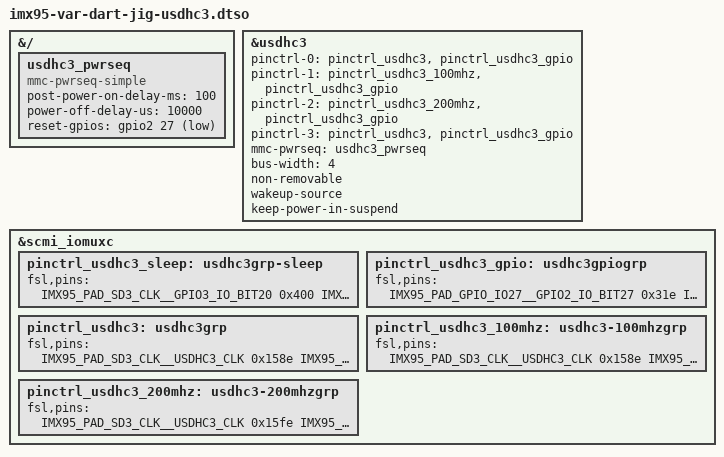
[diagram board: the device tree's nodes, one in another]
// SPDX-License-Identifier: (GPL-2.0+ OR MIT)
/*
 * Copyright 2023 NXP
 * Copyright 2024-2025 Variscite Ltd.
 */

#include "imx95-pinfunc.h"
#include <dt-bindings/gpio/gpio.h>

/dts-v1/;
/plugin/;
&{/} {
	usdhc3_pwrseq: usdhc3_pwrseq {
		compatible = "mmc-pwrseq-simple";
		post-power-on-delay-ms = <100>;
		power-off-delay-us = <10000>;
		reset-gpios = <&gpio2 27 GPIO_ACTIVE_LOW>;	/* WIFI_PWR_EN */
		status = "okay";
	};
};

/* WiFi */
&usdhc3 {
	pinctrl-names = "default","state_100mhz","state_200mhz","sleep";
	pinctrl-0 = <&pinctrl_usdhc3>, <&pinctrl_usdhc3_gpio>;
	pinctrl-1 = <&pinctrl_usdhc3_100mhz>, <&pinctrl_usdhc3_gpio>;
	pinctrl-2 = <&pinctrl_usdhc3_200mhz>, <&pinctrl_usdhc3_gpio>;
	pinctrl-3 = <&pinctrl_usdhc3>, <&pinctrl_usdhc3_gpio>;
	mmc-pwrseq = <&usdhc3_pwrseq>;
	bus-width = <4>;
	non-removable;
	wakeup-source;
	keep-power-in-suspend;
	status = "okay";
};

&scmi_iomuxc {

    pinctrl_usdhc3_sleep: usdhc3grp-sleep {
		fsl,pins = <
			IMX95_PAD_SD3_CLK__GPIO3_IO_BIT20		0x400
			IMX95_PAD_SD3_CMD__GPIO3_IO_BIT21		0x400
			IMX95_PAD_SD3_DATA0__GPIO3_IO_BIT22		0x400
			IMX95_PAD_SD3_DATA1__GPIO3_IO_BIT23		0x400
			IMX95_PAD_SD3_DATA2__GPIO3_IO_BIT24		0x400
			IMX95_PAD_SD3_DATA3__GPIO3_IO_BIT25		0x400
		>;
	};

	pinctrl_usdhc3_gpio: usdhc3gpiogrp {
		fsl,pins = <
			IMX95_PAD_GPIO_IO27__GPIO2_IO_BIT27				0x31e
			IMX95_PAD_CCM_CLKO4__GPIO4_IO_BIT29				0x31e
		>;
	};

	pinctrl_usdhc3: usdhc3grp {
		fsl,pins = <
			IMX95_PAD_SD3_CLK__USDHC3_CLK					0x158e
			IMX95_PAD_SD3_CMD__USDHC3_CMD					0x138e
			IMX95_PAD_SD3_DATA0__USDHC3_DATA0				0x138e
			IMX95_PAD_SD3_DATA1__USDHC3_DATA1				0x138e
			IMX95_PAD_SD3_DATA2__USDHC3_DATA2				0x138e
			IMX95_PAD_SD3_DATA3__USDHC3_DATA3				0x138e
		>;
	};

	pinctrl_usdhc3_100mhz: usdhc3-100mhzgrp {
		fsl,pins = <
			IMX95_PAD_SD3_CLK__USDHC3_CLK					0x158e
			IMX95_PAD_SD3_CMD__USDHC3_CMD					0x138e
			IMX95_PAD_SD3_DATA0__USDHC3_DATA0				0x138e
			IMX95_PAD_SD3_DATA1__USDHC3_DATA1				0x138e
			IMX95_PAD_SD3_DATA2__USDHC3_DATA2				0x138e
			IMX95_PAD_SD3_DATA3__USDHC3_DATA3				0x138e
		>;
	};

	pinctrl_usdhc3_200mhz: usdhc3-200mhzgrp {
		fsl,pins = <
			IMX95_PAD_SD3_CLK__USDHC3_CLK					0x15fe
			IMX95_PAD_SD3_CMD__USDHC3_CMD					0x13fe
			IMX95_PAD_SD3_DATA0__USDHC3_DATA0				0x13fe
			IMX95_PAD_SD3_DATA1__USDHC3_DATA1				0x13fe
			IMX95_PAD_SD3_DATA2__USDHC3_DATA2				0x13fe
			IMX95_PAD_SD3_DATA3__USDHC3_DATA3				0x13fe
		>;
	};

	/delete-node/ pinctrl_usdhc3_sdex;
};
